# uart_revb_me30 register map
Registers are access not given, no defined reset value unless marked. A register's access mark holds for its fields unless they carry their own. Offsets are from the block's base; lines under a group give offsets from that group; [hi:lo] are bit positions; {n}, {i} and the like mark numbered series; 'fields as' and 'values as' point back to an identical list; <NAME> marks a mode.

## Memory map
0x40042000 UART size 0x1000 — UART Low Power Registers

## UART — UART Low Power Registers
Base 0x40042000
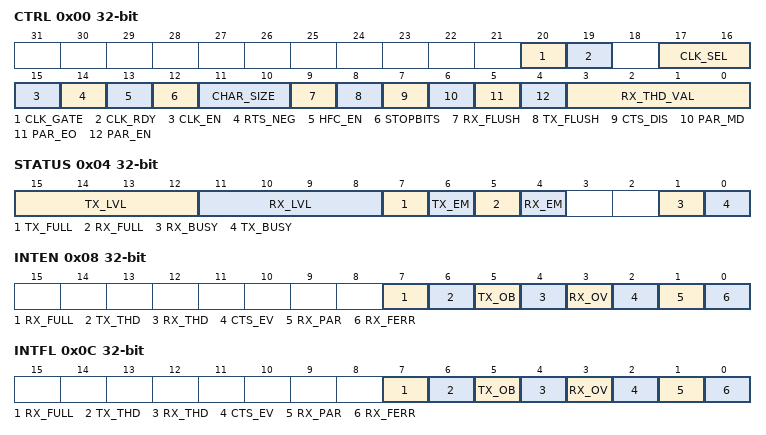
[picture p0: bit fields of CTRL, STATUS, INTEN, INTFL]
0x00 CTRL — Control register
  [20] CLK_GATE — UART Clock Auto Gating mode
  [19] CLK_RDY — Baud clock Ready read only bit
  [17:16] CLK_SEL — To select the UART clock source for the UART engine (except APB registers). Secondary clock (used for baud rate generator) can be asynchronous from APB clock.
    0=PERIPHERAL_CLOCK (APB Clock.); 1=CLK1 (IBRO clock.)
  [15] CLK_EN — Baud clock enable
  [14] RTS_NEG — The condition to negate RTS in HFC mode.
  [13] HFC_EN — Enables/disables hardware flow control
  [12] STOPBITS — Selects the number of stop bits. When 0: 1 stop bit. When 1: 1.5 stop bits for 5-bit characters (CHAR_SIZE=0); 2 stop bits for 6, 7, or 8-bit characters.
    0=1 stop bit; 1=1_5_OR_2 (1.5 stop bits for 5-bit characters (CHAR_SIZE=0); 2 stop bits for 6, 7, or 8-bit characters.)
  [11:10] CHAR_SIZE — Selects UART character size
    {v}={v+5}bits (v=0..3)
  [9] RX_FLUSH — Flushes the RX FIFO buffer. This bit is automatically cleared by hardware when flush is completed.
  [8] TX_FLUSH — Flushes the TX FIFO buffer. This bit is automatically cleared by hardware when flush is completed.
  [7] CTS_DIS — CTS Sampling Disable
  [6] PAR_MD — Selects parity based on 1s or 0s count (when PAREN=1)
  [5] PAR_EO — when PAREN=1 selects odd or even parity odd is 1 even is 0
  [4] PAR_EN — Parity Enable
  [3:0] RX_THD_VAL — This field specifies the depth of receive FIFO for interrupt generation (value 0 and > 16 are ignored)
0x04 STATUS ro
  [15:12] TX_LVL — Indicates the number of bytes currently in the TX FIFO (0-TX FIFO_ELTS)
  [11:8] RX_LVL — Indicates the number of bytes currently in the RX FIFO (0-RX FIFO_ELTS)
  [7] TX_FULL — Read-only flag indicating the TX FIFO state
  [6] TX_EM — Read-only flag indicating the TX FIFO state
  [5] RX_FULL — Read-only flag indicating the RX FIFO state
  [4] RX_EM — Read-only flag indicating the RX FIFO state
  [1] RX_BUSY — Read-only flag indicating the UART receiver status
  [0] TX_BUSY — Read-only flag indicating the UART transmit status
0x08 INTEN — Interrupt Enable control register
  [7] RX_FULL — Enable for RX FIFO Full interrupt.
  [6] TX_THD — Enable Interrupt for when TX FIFO meets or passes the threshold level.
  [5] TX_OB — Enable Interrupt For TX FIFO when only one byte is remaining.
  [4] RX_THD — Enable Interrupt For RX FIFO reaches the number of bytes configured by RXTHD
  [3] RX_OV — Enable Interrupt For RX FIFO Overrun Error
  [2] CTS_EV — Enable Interrupt For CTS signal change Event
  [1] RX_PAR — Enable Interrupt For RX Parity Error
  [0] RX_FERR — Enable Interrupt For RX Frame Error
0x0C INTFL — Interrupt status flags Control register
  [7] RX_FULL write-1-clears — Flag for full RX FIFO.
  [6] TX_THD write-1-clears — Flag for interrupt when TX FIFO meets or passes the threshold level.
  [5] TX_OB write-1-clears — Flag for interrupt when TX FIFO has only one byte is remaining.
  [4] RX_THD write-1-clears — Flag for interrupt when RX FIFO reaches the number of bytes configured by the RXTHD field
  [3] RX_OV write-1-clears — Flag for RX FIFO Overrun interrupt
  [2] CTS_EV write-1-clears — Flag for CTS signal change interrupt (hardware flow control disabled)
  [1] RX_PAR write-1-clears — Flag for RX Parity Error interrupt
  [0] RX_FERR write-1-clears — Flag for RX Frame Error Interrupt.
0x10 CLKDIV — Clock Divider register
  [19:0] CLKDIV — Baud rate divisor value
0x14 OSR — Over Sampling Rate register
  [2:0] OSR
0x18 TXPEEK — TX FIFO Output Peek register
  [7:0] DATA — Read TX FIFO next data. Reading from this field does not affect the contents of TX FIFO. Note that the parity bit is available from this field.
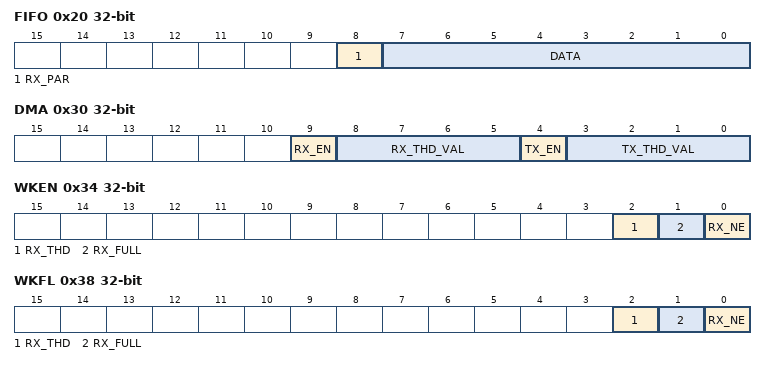
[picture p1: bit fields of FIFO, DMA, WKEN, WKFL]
0x20 FIFO — FIFO Read/Write register
  [8] RX_PAR — Parity error flag for next byte to be read from FIFO.
  [7:0] DATA — Load/unload location for TX and RX FIFO buffers.
0x30 DMA — DMA Configuration register
  [9] RX_EN — RX DMA channel enable
  [8:5] RX_THD_VAL — Rx FIFO Level DMA Trigger If the RX FIFO level is greater than this value, then the RX FIFO DMA interface will send a signal to the system DMA to notify that RX FIFO has characters to transfer to memory.
  [4] TX_EN — TX DMA channel enable
  [3:0] TX_THD_VAL — TX FIFO Level DMA Trigger If the TX FIFO level is less than this value, then the TX FIFO DMA interface will send a signal to system DMA to notify that TX FIFO is ready to receive data from memory.
0x34 WKEN — Wake up enable Control register
  [2] RX_THD — Wake-Up Enable for RX FIFO Threshold Met
  [1] RX_FULL — Wake-Up Enable for RX FIFO Full
  [0] RX_NE — Wake-Up Enable for RX FIFO Not Empty
0x38 WKFL — Wake up Flags register
  [2] RX_THD — Wake-Up Flag for RX FIFO Threshold Met
  [1] RX_FULL — Wake-Up Flag for RX FIFO Full
  [0] RX_NE — Wake-Up Flag for RX FIFO Not Empty
